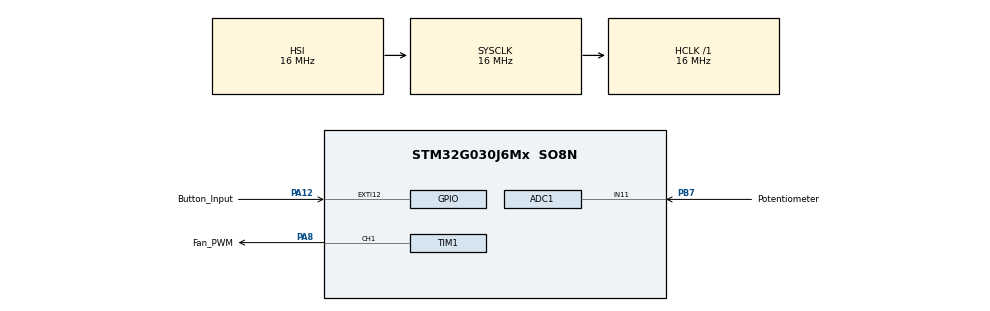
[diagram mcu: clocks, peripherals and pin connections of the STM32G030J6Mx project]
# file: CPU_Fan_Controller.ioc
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ADC1.Channel-0\#ChannelRegularConversion=ADC_CHANNEL_11
ADC1.NbrOfConversionFlag=1
ADC1.Rank-0\#ChannelRegularConversion=1
ADC1.SamplingTime-0\#ChannelRegularConversion=ADC_SAMPLINGTIME_COMMON_1
ADC1.SelectedChannel=ADC_CHANNEL_11
ADC1.master=1
Mcu.Family=STM32G0
Mcu.Name=STM32G030J6Mx
Mcu.Package=SO8N
NRST__PA0__PA1__PA2.StandardMode=true
NVIC.EXTI4_15_IRQn=true\:0\:0\:false\:false\:true\:true\:true\:true
PA12\ [PA10].GPIO_Label=Button_Input
PA12\ [PA10].GPIO_PuPd=GPIO_PULLDOWN
PA12\ [PA10].Signal=GPXTI12
PA14-BOOT0__PA15__PB5__PB6.StandardMode=true
PA8.GPIO_Label=Fan_PWM
PA8.Signal=S_TIM1_CH1
PB0__PB1__PA8__PA11\ [PA9].StandardMode=true
PB7.GPIO_Label=Potentiometer
PB7.Mode=IN11
PB7.Signal=ADC1_IN11
PC14-OSC32_IN\ (PC14)__PB7__PB8__PB9.StandardMode=true
ProjectManager.HeapSize=0x200
ProjectManager.StackSize=0x400
ProjectManager.TargetToolchain=STM32CubeIDE
RCC.AHBFreq_Value=16000000
RCC.CortexFreq_Value=16000000
RCC.EXTERNAL_CLOCK_VALUE=12288000
RCC.HCLKFreq_Value=16000000
RCC.HSE_VALUE=8000000
RCC.HSI_VALUE=16000000
RCC.LSE_VALUE=32768
RCC.SYSCLKFreq_VALUE=16000000
RCC.VCOOutputFreq_Value=128000000
SH.S_TIM1_CH1.0=TIM1_CH1,PWM Generation1 CH1
TIM1.Channel-PWM\ Generation1\ CH1=TIM_CHANNEL_1
TIM1.OCPolarity_1=TIM_OCPOLARITY_HIGH
TIM1.Period=639
TIM1.Prescaler=0
TIM1.Pulse-PWM\ Generation1\ CH1=320
board=custom

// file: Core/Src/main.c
/* USER CODE BEGIN Header */
/*
 * @Author Joseph Douglas
 * @Date   8/28/2023
 * @Description Start, stop ,and adjust PWM for a CPU fan
 * */
/**
  ******************************************************************************
  * @file           : main.c
  * @brief          : Main program body
  ******************************************************************************
  * @attention
  *
  * Copyright (c) 2023 STMicroelectronics.
  * All rights reserved.
  *
  * This software is licensed under terms that can be found in the LICENSE file
  * in the root directory of this software component.
  * If no LICENSE file comes with this software, it is provided AS-IS.
  *
  ******************************************************************************
  */
/* USER CODE END Header */
#include "main.h"
#include "adc.h"
#include "tim.h"
#include "gpio.h"

/* USER CODE BEGIN PV */
uint8_t isFanSpinning = 0;
uint32_t ADCValue_u32 = 0;
uint32_t previousADCValue_u32 = 0;
/* USER CODE END PV */

void SystemClock_Config(void);

int main(void)
{

  /* MCU Configuration--------------------------------------------------------*/

  /* Reset of all peripherals, Initializes the Flash interface and the Systick. */
  HAL_Init();

  /* Configure the system clock */
  SystemClock_Config();

  /* Initialize all configured peripherals */
  MX_GPIO_Init();
  MX_ADC1_Init();
  MX_TIM1_Init();
  /* USER CODE BEGIN 2 */
  /* Infinite loop */
  while (1)
  {
  }
}

void SystemClock_Config(void)
{
  RCC_OscInitTypeDef RCC_OscInitStruct = {0};
  RCC_ClkInitTypeDef RCC_ClkInitStruct = {0};

  /** Configure the main internal regulator output voltage
  */
  HAL_PWREx_ControlVoltageScaling(PWR_REGULATOR_VOLTAGE_SCALE1);

  /** Initializes the RCC Oscillators according to the specified parameters
  * in the RCC_OscInitTypeDef structure.
  */
  RCC_OscInitStruct.OscillatorType = RCC_OSCILLATORTYPE_HSI;
  RCC_OscInitStruct.HSIState = RCC_HSI_ON;
  RCC_OscInitStruct.HSIDiv = RCC_HSI_DIV1;
  RCC_OscInitStruct.HSICalibrationValue = RCC_HSICALIBRATION_DEFAULT;
  RCC_OscInitStruct.PLL.PLLState = RCC_PLL_NONE;
  if (HAL_RCC_OscConfig(&RCC_OscInitStruct) != HAL_OK)
  {
    Error_Handler();
  }

  /** Initializes the CPU, AHB and APB buses clocks
  */
  RCC_ClkInitStruct.ClockType = RCC_CLOCKTYPE_HCLK|RCC_CLOCKTYPE_SYSCLK
                              |RCC_CLOCKTYPE_PCLK1;
  RCC_ClkInitStruct.SYSCLKSource = RCC_SYSCLKSOURCE_HSI;
  RCC_ClkInitStruct.AHBCLKDivider = RCC_SYSCLK_DIV1;
  RCC_ClkInitStruct.APB1CLKDivider = RCC_HCLK_DIV1;

  if (HAL_RCC_ClockConfig(&RCC_ClkInitStruct, FLASH_LATENCY_0) != HAL_OK)
  {
    Error_Handler();
  }
}

void Error_Handler(void)
{
  __disable_irq();
  while (1)
  {
  }
}
